# MCU_FSS0_OSPI0_CTRL register map
Vendor: Texas Instruments
Peripheral module from a debugger description file (folder J7VCL).
Registers are 32-bit, access per field, reset 0x0 unless marked. A register's access mark holds for its fields unless they carry their own. Offsets are as the file gives them; lines under a group give offsets from that group; [hi:lo] are bit positions; {n}, {i} and the like mark numbered series; 'fields as' and 'values as' point back to an identical list; <NAME> marks a mode.

## MCU_FSS0_OSPI0_CTRL
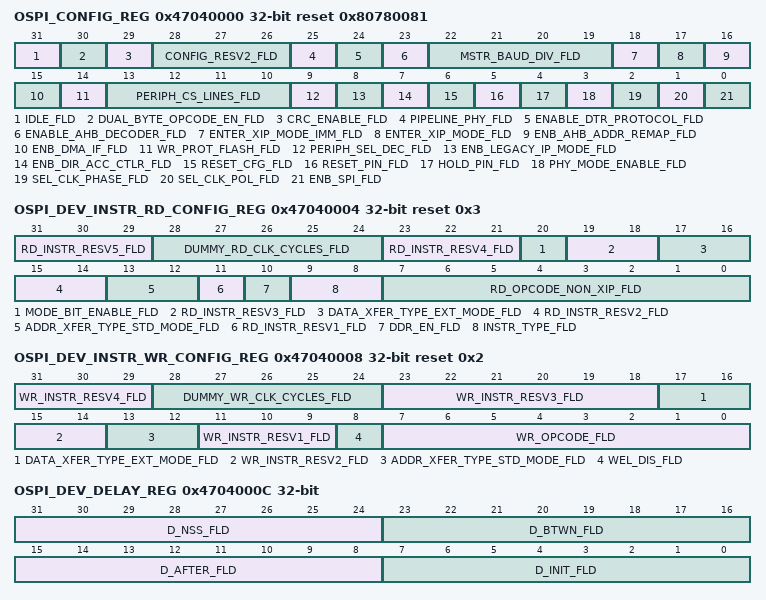
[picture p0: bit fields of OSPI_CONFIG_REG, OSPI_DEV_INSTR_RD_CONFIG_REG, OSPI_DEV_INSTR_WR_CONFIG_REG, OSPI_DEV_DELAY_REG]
0x47040000 OSPI_CONFIG_REG reset 0x80780081 — OSPI Configuration Register This register contains basic configuration fields of the controller. Some of the OSPI features described in this section may not be supported on this family of devices. For more information, see , OSPI Not Supported Features.
  [31] IDLE_FLD ro — Serial interface and low level SPI pipeline is IDLE.
  [30] DUAL_BYTE_OPCODE_EN_FLD rw — Dual-byte Opcode Mode enable bit.
  [29] CRC_ENABLE_FLD rw — CRC enable bit.
  [28:26] CONFIG_RESV2_FLD ro — Reserved
  [25] PIPELINE_PHY_FLD rw — Pipeline PHY Mode enable.
  [24] ENABLE_DTR_PROTOCOL_FLD rw — Enable DTR Protocol.
  [23] ENABLE_AHB_DECODER_FLD rw — Enable AHB Decoder. 0h = Active slave is selected based on the OSPI_CONFIG_REG[13:10] PERIPH_CS_LINES_FLD. 1h = Active slave is selected based on actual data interface address (the partition is calculated with respect to bits OSPI_DEV_SIZE_CONFIG_REG[28:21]).
  [22:19] MSTR_BAUD_DIV_FLD rw — Master mode baud rate divisor (2 to 32),
  [18] ENTER_XIP_MODE_IMM_FLD rw — Enter XIP Mode immediately.0h = If XIP is enabled, then setting to 0 will cause the controller to exit XIP mode on the next READ instruction Value=1h = Operate the device in XIP mode immediately. Use this register when the external device wakes up in XIP mode [as per the contents of its non-volatile configuration register]. The controller will assume the next READ instruction will be passed to the device as an XIP instruction, and therefore will not require the READ opcode to be transferred.Note: To exit XIP mode, this bit should be set to 0. This will take effect in the attached device only after the next READ instruction is executed. Software therefore should ensure that at least one READ instruction is requested after resetting this bit in order to be sure that XIP mode is exited.
  [17] ENTER_XIP_MODE_FLD rw — Enter XIP Mode on next READ.0h = If XIP is enabled, then setting to 0 will cause the controller to exit XIP mode on the next READ instruction.1h = If XIP is disabled, then setting to 1 will inform the controller that the device is ready to enter XIP on the next READ instruction. The controller will therefore send the appropriate command sequence, including mode bits to cause the device to enter XIP mode. Use this register after the controller has ensured the FLASH device has been configured to be ready to enter XIP mode. Note: To exit XIP mode, this bit should be set to 0. This will take effect in the attached device only AFTER the next READ instruction is executed. Software should therefore ensure that at least one READ instruction is requested after resetting this bit before it can be sure XIP mode in the device is exited
  [16] ENB_AHB_ADDR_REMAP_FLD rw — Enable Data Interface Address Remapping [Direct Access Mode Only]
  [15] ENB_DMA_IF_FLD rw — Enable DMA Peripheral Interface.
  [14] WR_PROT_FLASH_FLD rw — Write Protect Flash Pin.
  [13:10] PERIPH_CS_LINES_FLD rw — Peripheral Chip Select Lines.If OSPI_CONFIG_REG[9] PERIPH_SEL_DEC_FLD = 0, ss[3:0] are output thus:else ss[3-0] directly drives N_SS_OUT[3-0] .
  [9] PERIPH_SEL_DEC_FLD rw — Peripheral select decode.0h = only 1 of 4 selects N_SS_OUT[3:0] is active,1h = allow external 4-to-16 decode [N_SS_OUT = ss]
  [8] ENB_LEGACY_IP_MODE_FLD rw — Legacy IP Mode Enable.0h = Use Direct Access Controller/Indirect Access Controller 1h = Legacy Mode is enabled. In this mode, any write to the controller via the data interface is serialized and sent to the FLASH device. Any valid data read will pop the internal RX-FIFO, retrieving data that was forwarded by the external FLASH device on the SPI lines, 4, 2 or 1 byte transfers are permitted and controlled.
  [7] ENB_DIR_ACC_CTLR_FLD rw — Enable Direct Access Controller.0h = Disable the Direct Access Controller once current transfer of the data word is complete.1h = Enable the Direct Access Controller. When the Direct Access Controller and Indirect Access Controller are both disabled, all data requests are completed with an error response.
  [6] RESET_CFG_FLD rw — RESET pin configuration.0h = RESET feature on DQ3 pin of the device 1h = RESET feature on dedicated pin of the device [controlling of 5th bit influences on reset_out output].
  [5] RESET_PIN_FLD rw — Set to drive the RESET pin of the FLASH device and reset for de-activation of the RESET pin feature.
  [4] HOLD_PIN_FLD rw — Set to drive the HOLD pin of the FLASH device and reset for de-activation of the HOLD pin feature.
  [3] PHY_MODE_ENABLE_FLD rw — PHY mode enable.
  [2] SEL_CLK_PHASE_FLD rw — Select Clock Phase.Selects whether the clock is in an active or inactive phase outside the SPI word 0h = The SPI clock is active outside the word 1h = The SPI clock is inactive outside the word
  [1] SEL_CLK_POL_FLD rw — Clock polarity outside SPI word.0h = The SPI clock is quiescent low 1h = The SPI clock is quiescent high
  [0] ENB_SPI_FLD rw — OSPI Enable.0h = Disable the OSPI, once current transfer of the data wordis complete.1h = Enable the OSPI, when this bit is set to 0, all output enables are inactive and all pins are set to input mode.
0x47040004 OSPI_DEV_INSTR_RD_CONFIG_REG reset 0x3 — Device Read Instruction Configuration Register. This register defines the configuration of Multiple-SPI READ instruction. This register should be setup while the controller is idle.
  [31:29] RD_INSTR_RESV5_FLD ro — Reserved
  [28:24] DUMMY_RD_CLK_CYCLES_FLD rw — Dummy Read Clock Cycles.
  [23:21] RD_INSTR_RESV4_FLD ro — Reserved
  [20] MODE_BIT_ENABLE_FLD rw — Mode Bit Enable.
  [19:18] RD_INSTR_RESV3_FLD ro — Reserved
  [17:16] DATA_XFER_TYPE_EXT_MODE_FLD rw — Data Transfer Type for Standard SPI modes.0h = SIO mode data is shifted to the device on DQ0 only and from the device on DQ1 only 1h = Used for Dual Input/Output instructions For data transfers, DQ0 and DQ1 are used as both inputs and outputs 2h = Used for Quad Input/Output instructions For data transfers, DQ0, DQ1, DQ2, and DQ3 are used as both inputs and outputs 3h = Used for Octal Input/Output instructions For data transfers, DQ[7:0] are used as both inputs and outputs
  [15:14] RD_INSTR_RESV2_FLD ro — Reserved
  [13:12] ADDR_XFER_TYPE_STD_MODE_FLD rw — Address Transfer Type for Standard SPI modes.0h = Addresses can be shifted to the device on DQ0 only 1h = Addresses can be shifted to the device on DQ0 and DQ1 only 2h = Addresses can be shifted to the device on DQ0, DQ1, DQ2, and DQ3 3h = Addresses can be shifted to the device on DQ[7:0]
  [11] RD_INSTR_RESV1_FLD ro — Reserved
  [10] DDR_EN_FLD rw — DDR Enable.
  [9:8] INSTR_TYPE_FLD rw — Instruction Type.0h = Use Standard SPI mode [instruction always shifted into the device on DQ0 only] 1h = Use DIO-SPI mode [Instructions, Address and Data always sent on DQ0 and DQ1] 2h = Use QIO-SPI mode [Instructions, Address and Data always sent on DQ0, DQ1, DQ2, and DQ3] 3h = Use Octal-IO-SPI mode [Instructions, Address and Data always sent on DQ[7:0]]
  [7:0] RD_OPCODE_NON_XIP_FLD rw — Read Opcode in non-XIP mode: Read Opcode to use when not in XIP mode
0x47040008 OSPI_DEV_INSTR_WR_CONFIG_REG reset 0x2 — Device Write Instruction Configuration Register. This register defines the configuration of Multiple-SPI WRITE (Program Page) instruction. This register should be setup while the controller is idle.
  [31:29] WR_INSTR_RESV4_FLD ro — Reserved
  [28:24] DUMMY_WR_CLK_CYCLES_FLD rw — Dummy Write Clock Cycles.
  [23:18] WR_INSTR_RESV3_FLD ro — Reserved
  [17:16] DATA_XFER_TYPE_EXT_MODE_FLD rw — Data Transfer Type for Standard SPI modes.0h = SIO mode data is shifted to the device on DQ0 only and from the device on DQ1 only 1h = Used for Dual Input/Output instructions For data transfers, DQ0 and DQ1 are used as both inputs and outputs 2h = Used for Quad Input/Output instructions For data transfers, DQ0, DQ1, DQ2, and DQ3 are used as both inputs and outputs 3h = Used for Octal Input/Output instructions For data transfers, DQ[7:0] are used as both inputs and outputs
  [15:14] WR_INSTR_RESV2_FLD ro — Reserved
  [13:12] ADDR_XFER_TYPE_STD_MODE_FLD rw — Address Transfer Type for Standard SPI modes.0h = Addresses can be shifted to the device on DQ0 only 1h = Addresses can be shifted to the device on DQ0 and DQ1 only 2h = Addresses can be shifted to the device on DQ0, DQ1, DQ2. and DQ3 3h = Addresses can be shifted to the device on DQ[7:0]
  [11:9] WR_INSTR_RESV1_FLD ro — Reserved
  [8] WEL_DIS_FLD rw — WEL Disable.
  [7:0] WR_OPCODE_FLD rw — Write Opcode
0x4704000C OSPI_DEV_DELAY_REG rw — OSPI Device Delay Register. This register is used to introduce relative delays into the generation of the master output signals. All timings are defined in cycles of the OSPI REFERENCE CLOCK/ext_clk, defined in this table as SPI master ref clock. This register should be setup while the controller is idle.
  [31:24] D_NSS_FLD — Clock Delay for Chip Select Deassert.
  [23:16] D_BTWN_FLD — Clock Delay for Chip Select Deactivation.
  [15:8] D_AFTER_FLD — Clock Delay for Last Transaction Bit.
  [7:0] D_INIT_FLD — Clock Delay with N_SS_OUT.
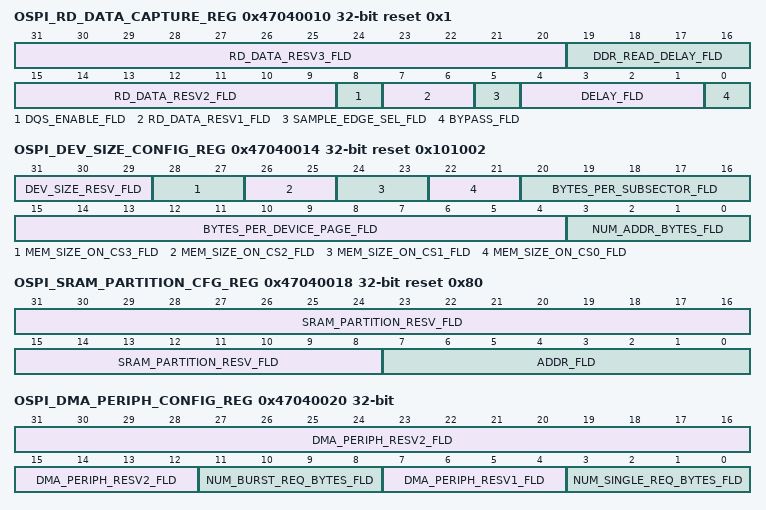
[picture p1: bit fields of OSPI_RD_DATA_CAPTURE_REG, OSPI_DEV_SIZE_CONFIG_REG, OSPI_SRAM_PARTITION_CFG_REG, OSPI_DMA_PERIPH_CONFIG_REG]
0x47040010 OSPI_RD_DATA_CAPTURE_REG reset 0x1 — Read Data Capture Register. This register is used to adjust SPI transfer conditions in order to fetch and capture data reliably. This register should be setup while the controller is idle.
  [31:20] RD_DATA_RESV3_FLD ro — Reserved
  [19:16] DDR_READ_DELAY_FLD rw — DDR read delay.
  [15:9] RD_DATA_RESV2_FLD ro — Reserved
  [8] DQS_ENABLE_FLD rw — DQS enable bit.
  [7:6] RD_DATA_RESV1_FLD ro — Reserved
  [5] SAMPLE_EDGE_SEL_FLD rw — Sample edge selection.
  [4:1] DELAY_FLD rw — Read Delay.
  [0] BYPASS_FLD rw — Bypass.
0x47040014 OSPI_DEV_SIZE_CONFIG_REG reset 0x101002 — Device Size Configuration Register. This register allows to define the memory organization of using Flash Devices. This register should be setup while the controller is idle.
  [31:29] DEV_SIZE_RESV_FLD ro — Reserved
  [28:27] MEM_SIZE_ON_CS3_FLD rw — Size of Flash Device connected to CS[3] pin:0h = size of 512Mb 1h = size of 1Gb2h = size of 2Gb 3h = size of 4Gb
  [26:25] MEM_SIZE_ON_CS2_FLD rw — Size of Flash Device connected to CS[2] pin:0h = size of 512Mb1h = size of 1Gb 2h = size of 2Gb 3h = size of 4Gb
  [24:23] MEM_SIZE_ON_CS1_FLD rw — Size of Flash Device connected to CS[1] pin:0h = size of 512Mb1h = size of 1Gb 2h = size of 2Gb 3h = size of 4Gb
  [22:21] MEM_SIZE_ON_CS0_FLD rw — Size of Flash Device connected to CS[0] pin:0h = size of 512Mb1h = size of 1Gb 2h = size of 2Gb 3h = size of 4Gb
  [20:16] BYTES_PER_SUBSECTOR_FLD rw — Number of bytes per Block.
  [15:4] BYTES_PER_DEVICE_PAGE_FLD rw — Number of bytes per device page.
  [3:0] NUM_ADDR_BYTES_FLD rw — Number of address bytes.
0x47040018 OSPI_SRAM_PARTITION_CFG_REG reset 0x80 — SRAM Partition Configuration Register.
  [31:8] SRAM_PARTITION_RESV_FLD ro — Reserved
  [7:0] ADDR_FLD rw — Indirect Read Partition Size.
0x4704001C OSPI_IND_AHB_ADDR_TRIGGER_REG rw — Indirect AHB Address Trigger Register. This register allowsto define the address distinguishing DAC access from triggered INDAC one. This register should be setup while the controller is idle.
  [31:0] ADDR_FLD — Indirect Trigger Address.
0x47040020 OSPI_DMA_PERIPH_CONFIG_REG — DMA Peripheral Configuration Register. This register allows to define the parameters of DMA peripheral controller. This register should be setup while the controller is idle. Some of the OSPI features described in this section may not be supported on this family of devices. For more information, see , OSPI Not Supported Features.
  [31:12] DMA_PERIPH_RESV2_FLD ro — Reserved
  [11:8] NUM_BURST_REQ_BYTES_FLD rw — Number of Burst Bytes.
  [7:4] DMA_PERIPH_RESV1_FLD ro — Reserved
  [3:0] NUM_SINGLE_REQ_BYTES_FLD rw — Number of Single Bytes.
0x47040024 OSPI_REMAP_ADDR_REG rw — Remap Address Register. This register allows to define the address offset for DAC accesses. This register should be setup while the controller is idle.
  [31:0] VALUE_FLD — This register is used to remap an incoming data address to a different address used by the FLASH device.
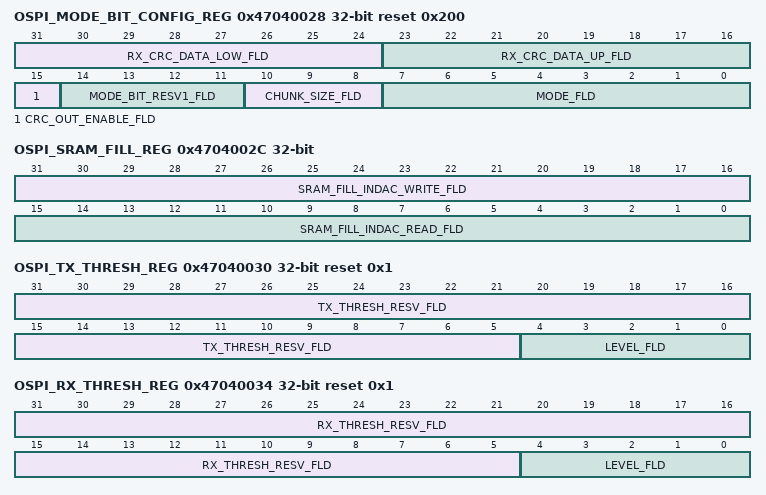
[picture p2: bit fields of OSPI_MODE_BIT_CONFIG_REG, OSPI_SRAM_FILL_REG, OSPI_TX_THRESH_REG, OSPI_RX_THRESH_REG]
0x47040028 OSPI_MODE_BIT_CONFIG_REG reset 0x200 — Mode Bit Configuration Register. This register allows to define the mode bits for corresponding Flash Device. It also provides configuration for CRC aware SPI transfers. This register should be setup while the controller is idle.
  [31:24] RX_CRC_DATA_LOW_FLD ro — RX CRC data [lower].
  [23:16] RX_CRC_DATA_UP_FLD ro — RX CRC data [upper].
  [15] CRC_OUT_ENABLE_FLD rw — CRC# output enable bit.
  [14:11] MODE_BIT_RESV1_FLD ro — Reserved
  [10:8] CHUNK_SIZE_FLD rw — It defines size of chunk after which CRC data is expected to show up on the SPI interface for write and read data transfers.
  [7:0] MODE_FLD rw — These are the 8 mode bits that are sent to the device following the address bytes if mode bit transmission has been enabled.
0x4704002C OSPI_SRAM_FILL_REG ro — SRAM Fill Register. This register keeps the values of current fill levels of both SRAM partitions.
  [31:16] SRAM_FILL_INDAC_WRITE_FLD — SRAM Fill Level [Indirect Write Partition].
  [15:0] SRAM_FILL_INDAC_READ_FLD — SRAM Fill Level [Indirect Read Partition].
0x47040030 OSPI_TX_THRESH_REG reset 0x1 — TX Threshold Register. This register allows to define the TX FIFO level arousing the corresponding interrupt. This register should be setup while the controller is idle.
  [31:5] TX_THRESH_RESV_FLD ro — Reserved
  [4:0] LEVEL_FLD rw — Defines the level at which the small TX FIFO not full interrupt is generated
0x47040034 OSPI_RX_THRESH_REG reset 0x1 — RX Threshold Register. This register allows to define the RX FIFO level arousing the corresponding interrupt. This register should be setup while the controller is idle.
  [31:5] RX_THRESH_RESV_FLD ro — Reserved
  [4:0] LEVEL_FLD rw — Defines the level at which the small RX FIFO not empty interrupt is generated.
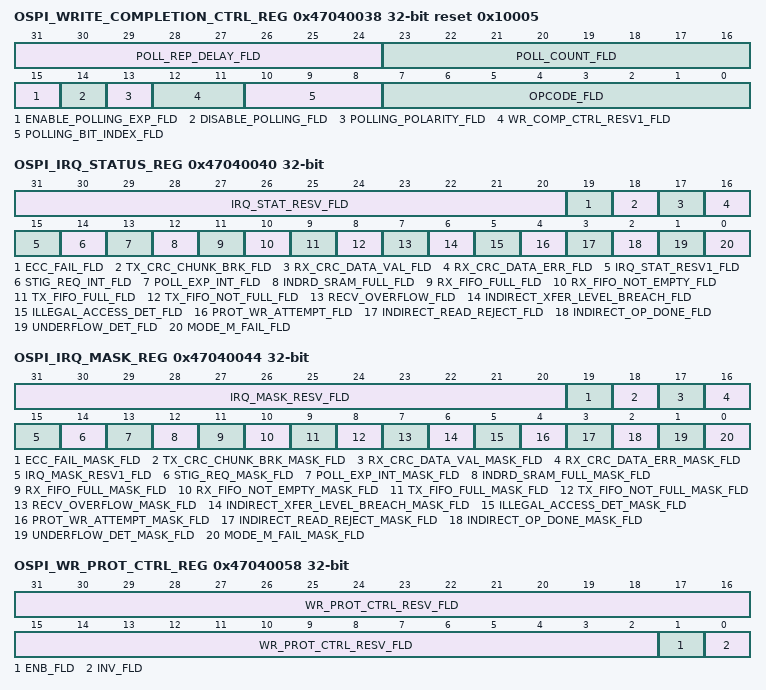
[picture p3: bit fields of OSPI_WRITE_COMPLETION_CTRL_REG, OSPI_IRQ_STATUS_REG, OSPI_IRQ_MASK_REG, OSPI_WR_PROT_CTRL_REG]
0x47040038 OSPI_WRITE_COMPLETION_CTRL_REG reset 0x10005 — Write Completion Control Register. This register defines how the controller will poll the device following a write transfer.
  [31:24] POLL_REP_DELAY_FLD rw — Polling repetition delay.
  [23:16] POLL_COUNT_FLD rw — Polling count.
  [15] ENABLE_POLLING_EXP_FLD rw — Enable polling expiration.
  [14] DISABLE_POLLING_FLD rw — Disable polling.
  [13] POLLING_POLARITY_FLD rw — Polling polarity.
  [12:11] WR_COMP_CTRL_RESV1_FLD ro — Reserved
  [10:8] POLLING_BIT_INDEX_FLD rw — Polling bit index.
  [7:0] OPCODE_FLD rw — Polling opcode.
0x4704003C OSPI_NO_OF_POLLS_BEF_EXP_REG rw reset 0xFFFFFFFF — Polling Expiration Register. This register defines maximum number of poll cycles. If the expected value of the bit being polled is not gotten after number defined in this register, the auto-polling is done on the next phase.
  [31:0] NO_OF_POLLS_BEF_EXP_FLD — Defines the numbers of poll cycles after which auto-polling phase terminates and polling expiration interrupt is generated.
0x47040040 OSPI_IRQ_STATUS_REG access not given — Interrupt Status Register. The status fields in this register are set when the described event occurs and the interrupt is enabled in the mask register. When any of these bit fields are set, the interrupt output is asserted high. The fields are each cleared by writing a 1 to the field. Note that bit fields 6 through 10 are only valid when legacy SPI mode is active.
  [31:20] IRQ_STAT_RESV_FLD ro — Reserved
  [19] ECC_FAIL_FLD — ECC failure. (access RW1C)
  [18] TX_CRC_CHUNK_BRK_FLD — TX CRC chunk was broken. (access RW1C)
  [17] RX_CRC_DATA_VAL_FLD — RX CRC data valid. (access RW1C)
  [16] RX_CRC_DATA_ERR_FLD — RX CRC data error. (access RW1C)
  [15] IRQ_STAT_RESV1_FLD ro — Reserved
  [14] STIG_REQ_INT_FLD — The controller is ready for getting another STIG request. (access RW1C)
  [13] POLL_EXP_INT_FLD — The maximum number of programmed polls cycles is expired. (access RW1C)
  [12] INDRD_SRAM_FULL_FLD — Indirect Read Partition overflow. (access RW1C)
  [11] RX_FIFO_FULL_FLD — Small RX FIFO full.Current FIFO status can be ignored in non-SPI legacy mode.0h = FIFO is not full 1h = FIFO is full (access RW1C)
  [10] RX_FIFO_NOT_EMPTY_FLD — Small RX FIFO not empty. Current FIFO status can be ignored in non-SPI legacy mode. 0h = FIFO has less than RX THRESHOLD entries. 1h = FIFO has &gt;= THRESHOLD entries. (access RW1C)
  [9] TX_FIFO_FULL_FLD — Small TX FIFO full. Current FIFO status can be ignored in non-SPI legacy mode 0h = FIFO is not full 1h = FIFO is full (access RW1C)
  [8] TX_FIFO_NOT_FULL_FLD — Small TX FIFO not full.Current FIFO status can be ignored in non-SPI legacy mode 0h = FIFO has &gt;= THRESHOLD entries.1h = FIFO has less than THRESHOLD entries. (access RW1C)
  [7] RECV_OVERFLOW_FLD — Receive Overflow. This should only occur in Legacy SPI mode. Set if an attempt is made to push the RX FIFO when it is full. This bit is reset only by a system reset and cleared only when this register is read If a new push to the RX FIFO occurs coincident with a register read this flag will remain set.0h = no overflow has been detected. 1h = an overflow has occurred. (access RW1C)
  [6] INDIRECT_XFER_LEVEL_BREACH_FLD — Indirect Transfer Watermark Level Breached. (access RW1C)
  [5] ILLEGAL_ACCESS_DET_FLD — Illegal AHB access has been detected AHB wrapping bursts and the use of SPLIT/RETRY accesses will cause this error interrupt to trigger. (access RW1C)
  [4] PROT_WR_ATTEMPT_FLD — Write to protected area was attempted and rejected. (access RW1C)
  [3] INDIRECT_READ_REJECT_FLD — Indirect operation was requested but could not be accepted. Two indirect operations already in storage. (access RW1C)
  [2] INDIRECT_OP_DONE_FLD — Indirect Operation Complete: Controller has completed last triggered indirect operation. (access RW1C)
  [1] UNDERFLOW_DET_FLD — Underflow Detected:0h = no underflow has been detected 1h = underflow is detected and an attempt to transfer data is made when the small TX FIFO is empty. This may occur when AHB write data is being supplied too slowly to keep up with the requested write operation. This bit is reset only by a system reset and cleared only when the register is read. (access RW1C)
  [0] MODE_M_FAIL_FLD — Mode M Failure. Mode M failure indicates the voltage on pin N_SS_IN is inconsistent with the SPI mode. Set =1 if N_SS_IN is low in master mode [multi-master contention]. These conditions will clear the spi_enable bit and disable the SPI. This bit is reset only by a system reset and cleared only when this register is: Read 0h = no mode fault has been detected.Read 1h = a mode fault has occurred. (access RW1C)
0x47040044 OSPI_IRQ_MASK_REG — Interrupt Mask Register. This register allows the user to mask/unmask particular interrupt sources. This register should be setup while the controller is idle. 0h = the interrupt for the corresponding interrupt status register bit is disabled. 1h = the interrupt for the corresponding interrupt status register bit is enabled.
  [31:20] IRQ_MASK_RESV_FLD ro — Reserved
  [19] ECC_FAIL_MASK_FLD rw — ECC failure Mask
  [18] TX_CRC_CHUNK_BRK_MASK_FLD rw — TX CRC chunk was broken Mask
  [17] RX_CRC_DATA_VAL_MASK_FLD rw — RX CRC data valid Mask
  [16] RX_CRC_DATA_ERR_MASK_FLD rw — RX CRC data error Mask
  [15] IRQ_MASK_RESV1_FLD ro — Reserved
  [14] STIG_REQ_MASK_FLD rw — STIG request completion Mask
  [13] POLL_EXP_INT_MASK_FLD rw — Polling expiration detected Mask
  [12] INDRD_SRAM_FULL_MASK_FLD rw — Indirect Read Partition overflow mask
  [11] RX_FIFO_FULL_MASK_FLD rw — Small RX FIFO full Mask
  [10] RX_FIFO_NOT_EMPTY_MASK_FLD rw — Small RX FIFO not empty Mask
  [9] TX_FIFO_FULL_MASK_FLD rw — Small TX FIFO full Mask
  [8] TX_FIFO_NOT_FULL_MASK_FLD rw — Small TX FIFO not full Mask
  [7] RECV_OVERFLOW_MASK_FLD rw — Receive Overflow Mask
  [6] INDIRECT_XFER_LEVEL_BREACH_MASK_FLD rw — Transfer Watermark Breach Mask
  [5] ILLEGAL_ACCESS_DET_MASK_FLD rw — Illegal Access Detected Mask
  [4] PROT_WR_ATTEMPT_MASK_FLD rw — Protected Area Write Attempt Mask
  [3] INDIRECT_READ_REJECT_MASK_FLD rw — Indirect Read Reject Mask
  [2] INDIRECT_OP_DONE_MASK_FLD rw — Indirect Complete Mask
  [1] UNDERFLOW_DET_MASK_FLD rw — Underflow Detected Mask
  [0] MODE_M_FAIL_MASK_FLD rw — Mode M Failure Mask
0x47040050 OSPI_LOWER_WR_PROT_REG rw — Lower Write Protection Register. This register allows to define lower boundary of the write protection area. This register should be setup while the controller is idle.
  [31:0] SUBSECTOR_FLD — Lower Block Number.The block number that defines the lower block in the range of blocks that is to be locked from writing.
0x47040054 OSPI_UPPER_WR_PROT_REG rw — Upper Write Protection Register. This register allows to define upper boundary of the write protection area. This register should be setup while the controller is idle.
  [31:0] SUBSECTOR_FLD — Lower Block Number.
0x47040058 OSPI_WR_PROT_CTRL_REG — Write Protection Control Register. This register allows to define the configuration of write protection settings. This register should be setup while the controller is idle.
  [31:2] WR_PROT_CTRL_RESV_FLD ro — Reserved
  [1] ENB_FLD rw — Write Protection Enable Bit.
  [0] INV_FLD rw — Write Protection Inversion Bit.
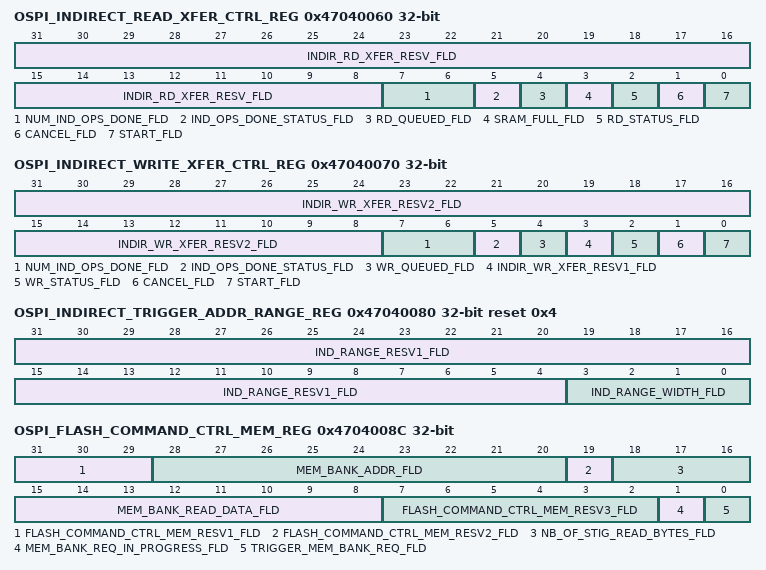
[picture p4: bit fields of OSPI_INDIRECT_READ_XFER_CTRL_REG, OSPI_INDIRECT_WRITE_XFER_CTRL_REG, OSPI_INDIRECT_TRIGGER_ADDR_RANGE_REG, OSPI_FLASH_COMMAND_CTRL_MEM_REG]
0x47040060 OSPI_INDIRECT_READ_XFER_CTRL_REG access not given — Indirect Read Transfer Control Register. This register allows control of the Indirect Read Transfer logic.
  [31:8] INDIR_RD_XFER_RESV_FLD ro — Reserved
  [7:6] NUM_IND_OPS_DONE_FLD ro — This field contains the number of indirect operations which have been completed.
  [5] IND_OPS_DONE_STATUS_FLD — Indirect Completion Status. (access RW1C)
  [4] RD_QUEUED_FLD ro — Queued Indirect Read Operations.
  [3] SRAM_FULL_FLD — SRAM Full. SRAM full and unable to immediately complete an indirect operation. Write a 1 to this field to clear it indirect operation [status]. (access RW1C)
  [2] RD_STATUS_FLD ro — Indirect Read Status.
  [1] CANCEL_FLD wo — Cancel Indirect Read.
  [0] START_FLD wo — Start Indirect Read.
0x47040064 OSPI_INDIRECT_READ_XFER_WATERMARK_REG rw — Indirect Read Transfer Watermark Register. This register allows to define watermark level for Indirect read transfers. This register should be setup before an indirect read transfer is triggered. Some of the OSPI features described in this section may not be supported on this family of devices. For more information, see , OSPI Not Supported Features.
  [31:0] LEVEL_FLD — Watermark Value.
0x47040068 OSPI_INDIRECT_READ_XFER_START_REG rw — Indirect Read Transfer Start Address Register. This register allows to define start address of indirect read transfer which is about to be triggered. This register should be setup before an indirect read transfer is triggered.
  [31:0] ADDR_FLD — Start of Indirect Access.
0x4704006C OSPI_INDIRECT_READ_XFER_NUM_BYTES_REG rw — Indirect Read Transfer Number Bytes Register. This register allows to define number of bytes to be read of indirect read transfer which is about to be triggered. This register should be setup before an indirect read transfer is triggered.
  [31:0] VALUE_FLD — Indirect Number of Bytes.
0x47040070 OSPI_INDIRECT_WRITE_XFER_CTRL_REG access not given — Indirect Write Transfer Control Register. This register allows control of the Indirect Write Transfer logic.
  [31:8] INDIR_WR_XFER_RESV2_FLD ro — Reserved
  [7:6] NUM_IND_OPS_DONE_FLD ro — This field contains the number of indirect operations which have been completed.
  [5] IND_OPS_DONE_STATUS_FLD — Indirect Completion Status. (access RW1C)
  [4] WR_QUEUED_FLD ro — Two indirect write operations have been queued.
  [3] INDIR_WR_XFER_RESV1_FLD ro — Reserved
  [2] WR_STATUS_FLD ro — Indirect Write Status.
  [1] CANCEL_FLD wo — Cancel Indirect Write.
  [0] START_FLD wo — Start Indirect Write.
0x47040074 OSPI_INDIRECT_WRITE_XFER_WATERMARK_REG rw reset 0xFFFFFFFF — Indirect Write Transfer Watermark Register. This register allows to define watermark level for Indirect write transfers. This register should be setup before an indirect write transfer is triggered. Some of the OSPI features described in this section may not be supported on this family of devices. For more information, see , OSPI Not Supported Features.
  [31:0] LEVEL_FLD — Watermark Value.
0x47040078 OSPI_INDIRECT_WRITE_XFER_START_REG rw — Indirect Write Transfer Start Address Register. This register allows to define start address of indirect write transfer which is about to be triggered. This register should be setup before an indirect write transfer is triggered.
  [31:0] ADDR_FLD — Start of Indirect Access.
0x4704007C OSPI_INDIRECT_WRITE_XFER_NUM_BYTES_REG rw — Indirect Write Transfer Number Bytes Register. This register allows to define number of bytes to be written of indirect read transfer which is about to be triggered. This register should be setup before an indirect read transfer is triggered.
  [31:0] VALUE_FLD — Indirect Number of Bytes.
0x47040080 OSPI_INDIRECT_TRIGGER_ADDR_RANGE_REG reset 0x4 — Indirect Trigger Address Range Register. This register allows the user to define the indirect trigger address range. If the configured range exceeds number of bytes programmed for particular indirect transfer, there is no need to detect indirect trigger address boundaries by software. This register should be setup before an indirect read transfer is triggered.
  [31:4] IND_RANGE_RESV1_FLD ro — Reserved
  [3:0] IND_RANGE_WIDTH_FLD rw — Indirect Range Width.
0x4704008C OSPI_FLASH_COMMAND_CTRL_MEM_REG — Flash Command Control Memory Register. This register controls the Memory Bank accesses. It also defines the number of bytes intended to get by STIG access configured to use the STIG Memory Bank.
  [31:29] FLASH_COMMAND_CTRL_MEM_RESV1_FLD ro — Reserved
  [28:20] MEM_BANK_ADDR_FLD rw — Memory Bank Address.
  [19] FLASH_COMMAND_CTRL_MEM_RESV2_FLD ro — Reserved
  [18:16] NB_OF_STIG_READ_BYTES_FLD rw — Number of STIG Memory Bank Read Bytes.
  [15:8] MEM_BANK_READ_DATA_FLD ro — Memory Bank Read Data.
  [7:2] FLASH_COMMAND_CTRL_MEM_RESV3_FLD ro — Reserved
  [1] MEM_BANK_REQ_IN_PROGRESS_FLD ro — Memory Bank data request in progress.
  [0] TRIGGER_MEM_BANK_REQ_FLD wo — Trigger the Memory Bank data request.
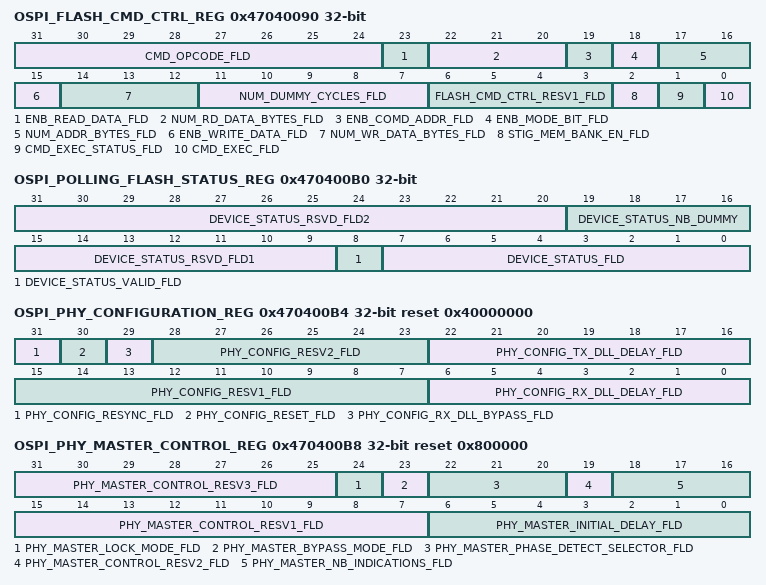
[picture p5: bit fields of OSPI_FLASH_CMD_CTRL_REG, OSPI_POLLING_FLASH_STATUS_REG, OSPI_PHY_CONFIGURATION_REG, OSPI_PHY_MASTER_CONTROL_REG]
0x47040090 OSPI_FLASH_CMD_CTRL_REG — Flash Command Control Register. This register controls SPI transactions generated by STIG. It allows to define corresponding SPI frame to particular command, triggering the transfer and polling for its completion.
  [31:24] CMD_OPCODE_FLD rw — Command Opcode.
  [23] ENB_READ_DATA_FLD rw — Read Data Enable. Set to 1 if the command specified in the OSPI_FLASH_CMD_CTRL_REG[31-24] CMD_OPCODE_FLD requires read data bytes to be received from the device.
  [22:20] NUM_RD_DATA_BYTES_FLD rw — Number of Read Data Bytes: Up to 8 data bytes may be read using this command Set to 0 for 1 byte and 7 for 8 bytes
  [19] ENB_COMD_ADDR_FLD rw — Command Address Enable.Set to 1 if the command specified in OSPI_FLASH_CMD_CTRL_REG[31-24] CMD_OPCODE_FLD requires an address This should be setup before triggering the command via writing a 1 to the execute field.
  [18] ENB_MODE_BIT_FLD rw — Mode Bit Enable: Set to 1 to ensure the mode bits as defined in the Mode Bit Configuration register are sent following the address bytes
  [17:16] NUM_ADDR_BYTES_FLD rw — Number of Address Bytes. Set to the number of address bytes required [the address itself is programmed in the OSPI_FLASH_CMD_ADDR_REG. This should be setup before triggering the command via the OSPI_FLASH_CMD_CTRL_REG[0] CMD_EXEC_FLD:0h = 1 address byte 1h = 2 address bytes 2h = 3 address bytes 3h = 4 address bytes
  [15] ENB_WRITE_DATA_FLD rw — Write Data Enable.
  [14:12] NUM_WR_DATA_BYTES_FLD rw — Number of Write Data Bytes.
  [11:7] NUM_DUMMY_CYCLES_FLD rw — Number of Dummy cycles.
  [6:3] FLASH_CMD_CTRL_RESV1_FLD ro — Reserved
  [2] STIG_MEM_BANK_EN_FLD rw — STIG Memory Bank enable bit.
  [1] CMD_EXEC_STATUS_FLD ro — Command execution in progress.
  [0] CMD_EXEC_FLD wo — Execute the command.
0x47040094 OSPI_FLASH_CMD_ADDR_REG rw — Flash Command Address Register. This register allows to define the address of the command using by the STIG controller. This register should be setup while the controller is idle.
  [31:0] ADDR_FLD — Command Address.
0x470400A0 OSPI_FLASH_RD_DATA_LOWER_REG ro — Flash Command Read Data Register (Lower). This register keeps the last 4 bytes read by STIG SPI access.
  [31:0] DATA_FLD — Command Read Data (Lower).
0x470400A4 OSPI_FLASH_RD_DATA_UPPER_REG ro — Flash Command Read Data Register (Upper). This register keeps the last but 4 bytes read by STIG SPI access. This register in conjunction with the register enables the controller to keep 8 last bytes read from the Flash Device using STIG.
  [31:0] DATA_FLD — Command Read Data (Upper).
0x470400A8 OSPI_FLASH_WR_DATA_LOWER_REG rw — Flash Command Write Data Register (Lower). This register takes the first 4 bytes to be written by STIG.
  [31:0] DATA_FLD — Command Write Data Lower Byte.
0x470400AC OSPI_FLASH_WR_DATA_UPPER_REG rw — Flash Command Write Data Register (Upper). This register takes the bytes ranging from 5 to 8 to be written by STIG.
  [31:0] DATA_FLD — Command Write Data Upper Byte.
0x470400B0 OSPI_POLLING_FLASH_STATUS_REG — Polling Flash Status Register. This register provides auto-polling data. It acts as the extension for the register where full status is not available and any action can be taken only relying on the indication of single bit being polled for.
  [31:20] DEVICE_STATUS_RSVD_FLD2 ro — Reserved
  [19:16] DEVICE_STATUS_NB_DUMMY rw — Number of dummy cycles for auto-polling.
  [15:9] DEVICE_STATUS_RSVD_FLD1 ro — Reserved
  [8] DEVICE_STATUS_VALID_FLD ro — Device Status Valid.
  [7:0] DEVICE_STATUS_FLD ro — Defines actual Status Register of Device.
0x470400B4 OSPI_PHY_CONFIGURATION_REG reset 0x40000000 — PHY Configuration Register. This register defines the configuration of PHY Module and controls the internal DLL. This register should be setup while the controller is idle.
  [31] PHY_CONFIG_RESYNC_FLD wo — Re-synchronisation DLL.
  [30] PHY_CONFIG_RESET_FLD wo — DLL Reset.
  [29] PHY_CONFIG_RX_DLL_BYPASS_FLD rw — RX DLL Bypass.
  [28:23] PHY_CONFIG_RESV2_FLD ro — Reserved
  [22:16] PHY_CONFIG_TX_DLL_DELAY_FLD rw — TX DLL Delay.
  [15:7] PHY_CONFIG_RESV1_FLD ro — Reserved
  [6:0] PHY_CONFIG_RX_DLL_DELAY_FLD rw — RX DLL Delay.
0x470400B8 OSPI_PHY_MASTER_CONTROL_REG reset 0x800000 — PHY DLL Master Control Register. This register defines the configuration and control logic of DLL intended to work in DLL Master Mode.
  [31:25] PHY_MASTER_CONTROL_RESV3_FLD ro — Reserved
  [24] PHY_MASTER_LOCK_MODE_FLD rw — Determines if the master delay line locks on a full cycle or half cycle of delay. This bit need not be written by software. If DLL does not lock in full cycle, it will automatically try to lock in half cycle mode.
  [23] PHY_MASTER_BYPASS_MODE_FLD rw — Controls the bypass mode of the master and slave DLLs.Master DLL is disabled with only 1 delay element in its delay line. The slave delay lines decode delays in absolute delay elements rather than as fractional delays.Delays are defined in
  [22:20] PHY_MASTER_PHASE_DETECT_SELECTOR_FLD rw — Selects the number of delay elements to be inserted between the phase detect flip-flops.
  [19] PHY_MASTER_CONTROL_RESV2_FLD ro — Reserved
  [18:16] PHY_MASTER_NB_INDICATIONS_FLD rw — Holds the number of consecutive increment or decrement indications.
  [15:7] PHY_MASTER_CONTROL_RESV1_FLD ro — Reserved
  [6:0] PHY_MASTER_INITIAL_DELAY_FLD rw — This value is the initial delay value for the Master DLL.
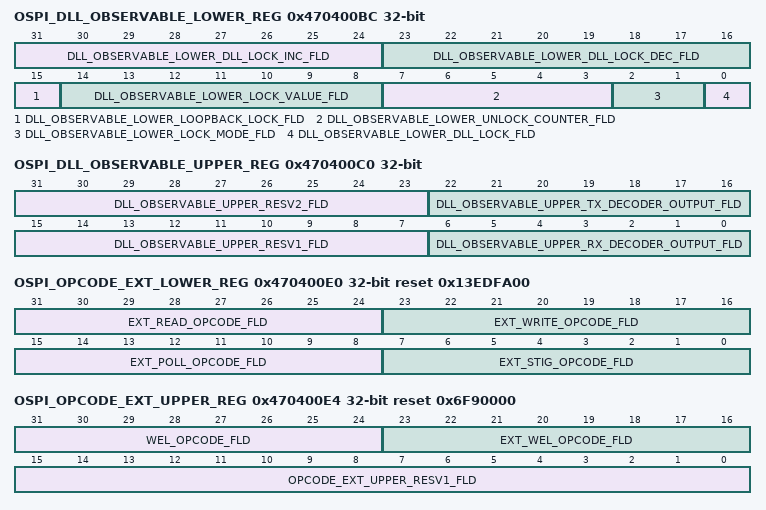
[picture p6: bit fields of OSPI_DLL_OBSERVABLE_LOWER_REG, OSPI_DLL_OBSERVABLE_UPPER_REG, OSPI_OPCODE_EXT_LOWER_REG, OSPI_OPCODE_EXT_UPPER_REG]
0x470400BC OSPI_DLL_OBSERVABLE_LOWER_REG ro — DLL Observable Register Lower. This register allows to observe and debug DLL status.
  [31:24] DLL_OBSERVABLE_LOWER_DLL_LOCK_INC_FLD — Holds the state of the cumulative lock incremental steps when the
  [23:16] DLL_OBSERVABLE_LOWER_DLL_LOCK_DEC_FLD — Holds the state of the cumulative lock decremental steps when the
  [15] DLL_OBSERVABLE_LOWER_LOOPBACK_LOCK_FLD — This bit indicates that lock of loopback is done.
  [14:8] DLL_OBSERVABLE_LOWER_LOCK_VALUE_FLD — DLL Lock Value.
  [7:3] DLL_OBSERVABLE_LOWER_UNLOCK_COUNTER_FLD — DLL Unlock Counter.
  [2:1] DLL_OBSERVABLE_LOWER_LOCK_MODE_FLD — DLL Locked Mode.
  [0] DLL_OBSERVABLE_LOWER_DLL_LOCK_FLD — DLL Lock.
0x470400C0 OSPI_DLL_OBSERVABLE_UPPER_REG ro — DLL Observable Register Upper. This register allows to observe and debug DLL status.
  [31:23] DLL_OBSERVABLE_UPPER_RESV2_FLD — Reserved
  [22:16] DLL_OBSERVABLE_UPPER_TX_DECODER_OUTPUT_FLD — TX DLL decoder output.
  [15:7] DLL_OBSERVABLE_UPPER_RESV1_FLD — Reserved
  [6:0] DLL_OBSERVABLE_UPPER_RX_DECODER_OUTPUT_FLD — RX DLL decoder output.
0x470400E0 OSPI_OPCODE_EXT_LOWER_REG rw reset 0x13EDFA00 — Opcode Extension Register (Lower). This register provides the supplementing opcodes for Dual Byte Opcode Mode activated by [30] DUAL_BYTE_OPCODE_EN_FLD bit.
  [31:24] EXT_READ_OPCODE_FLD — Supplement byte of any Read Opcoded defined in the
  [23:16] EXT_WRITE_OPCODE_FLD — Supplement byte of any Write Opcode defined in the
  [15:8] EXT_POLL_OPCODE_FLD — Supplement byte of any Polling Opcode defined in the
  [7:0] EXT_STIG_OPCODE_FLD — Supplement byte of any STIG Opcode defined in the
0x470400E4 OSPI_OPCODE_EXT_UPPER_REG reset 0x6F90000 — Opcode Extension Register (Upper). This register provides the supplementing opcodes for Dual Byte Opcode Mode activated by [30] DUAL_BYTE_OPCODE_EN_FLD bit.
  [31:24] WEL_OPCODE_FLD rw — WEL Opcode byte 1.
  [23:16] EXT_WEL_OPCODE_FLD rw — WEL Opcode byte 2 (Optional).
  [15:0] OPCODE_EXT_UPPER_RESV1_FLD ro — Reserved
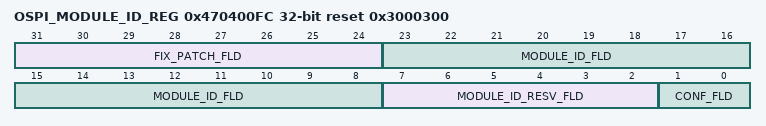
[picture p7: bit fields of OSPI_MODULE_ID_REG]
0x470400FC OSPI_MODULE_ID_REG ro reset 0x3000300 — Module ID Register. This register provides the IP release number and the configuration data.
  [31:24] FIX_PATCH_FLD — Fix/path number related to revision described by 3 LSBs of this register
  [23:8] MODULE_ID_FLD — Module/Revision ID number
  [7:2] MODULE_ID_RESV_FLD — Reserved
  [1:0] CONF_FLD — Configuration ID number:0h = OCTAL + PHY Configuration 1h = OCTAL Configuration 2h = QUAD + PHY Configuration 3h = QUAD Configuration
